AUTOSAR XML (schema 00046)
package /ComponentTypes
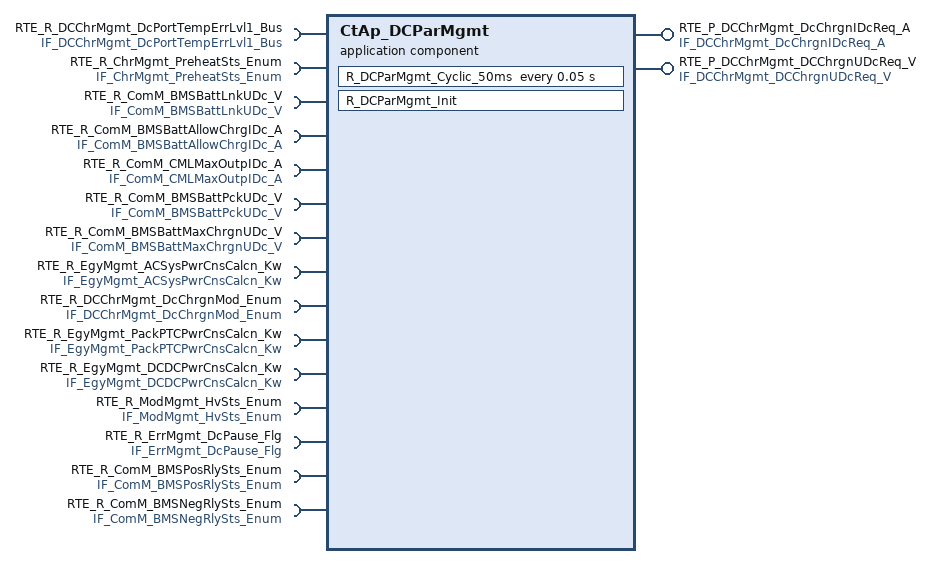
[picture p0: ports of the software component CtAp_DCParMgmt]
  application sw component type CtAp_DCParMgmt
    provide port RTE_P_DCChrMgmt_DcChrgnIDcReq_A: nonqueued-sender-com-spec{data-element=tec_DCChrMgmt_DcChrgnIDcReq_A, init-value=0}, provided-interface=IF_DCChrMgmt_DcChrgnIDcReq_A
    provide port RTE_P_DCChrMgmt_DCChrgnUDcReq_V: nonqueued-sender-com-spec{data-element=tec_DCChrMgmt_DcChrgnUDcReq_V, init-value=0}, provided-interface=IF_DCChrMgmt_DCChrgnUDcReq_V
    15 x require port:
      RTE_R_DCChrMgmt_DcPortTempErrLvl1_Bus: nonqueued-receiver-com-spec{data-element=tec_DCChrMgmt_DcPortTempErrLvl1_Bus, filter=data-filter-type=ALWAYS, init-value=fields=[DCChrMgmt_MonStatDcPortTempErrLvl1:0, DCChrMgmt_MonResDcPortTempErrLvl1:0, DCChrMgmt_ErrStatDcPortTempErrLvl1:0, DCChrMgmt_ErrResDcPortTempErrLvl1:0]}, required-interface=IF_DCChrMgmt_DcPortTempErrLvl1_Bus
      RTE_R_ChrMgmt_PreheatSts_Enum: nonqueued-receiver-com-spec{data-element=tec_ChrMgmt_PreheatSts_Enum, filter=data-filter-type=ALWAYS, init-value=0}, required-interface=IF_ChrMgmt_PreheatSts_Enum
      RTE_R_ComM_BMSBattLnkUDc_V: nonqueued-receiver-com-spec{data-element=tec_ComM_BMSBattLnkUDc_V, filter=data-filter-type=ALWAYS, init-value=0}, required-interface=IF_ComM_BMSBattLnkUDc_V
      RTE_R_ComM_BMSBattAllowChrgIDc_A: nonqueued-receiver-com-spec{data-element=tec_ComM_BMSBattAllowChrgIDc_A, filter=data-filter-type=ALWAYS, init-value=0}, required-interface=IF_ComM_BMSBattAllowChrgIDc_A
      RTE_R_ComM_CMLMaxOutpIDc_A: nonqueued-receiver-com-spec{data-element=tec_ComM_CMLMaxOutpIDc_A, filter=data-filter-type=ALWAYS, init-value=0}, required-interface=IF_ComM_CMLMaxOutpIDc_A
      RTE_R_ComM_BMSBattPckUDc_V: nonqueued-receiver-com-spec{data-element=tec_ComM_BMSBattPckUDc_V, filter=data-filter-type=ALWAYS, init-value=0}, required-interface=IF_ComM_BMSBattPckUDc_V
      RTE_R_ComM_BMSBattMaxChrgnUDc_V: nonqueued-receiver-com-spec{data-element=tec_ComM_BMSBattMaxChrgnUDc_V, filter=data-filter-type=ALWAYS, init-value=0}, required-interface=IF_ComM_BMSBattMaxChrgnUDc_V
      RTE_R_EgyMgmt_ACSysPwrCnsCalcn_Kw: nonqueued-receiver-com-spec{data-element=tec_EgyMgmt_ACSysPwrCnsCalcn_Kw, filter=data-filter-type=ALWAYS, init-value=0}, required-interface=IF_EgyMgmt_ACSysPwrCnsCalcn_Kw
      RTE_R_DCChrMgmt_DcChrgnMod_Enum: nonqueued-receiver-com-spec{data-element=tec_DCChrMgmt_DcChrgnMod_Enum, filter=data-filter-type=ALWAYS, init-value=0}, required-interface=IF_DCChrMgmt_DcChrgnMod_Enum
      RTE_R_EgyMgmt_PackPTCPwrCnsCalcn_Kw: nonqueued-receiver-com-spec{data-element=tec_EgyMgmt_PackPTCPwrCnsCalcn_Kw, filter=data-filter-type=ALWAYS, init-value=0}, required-interface=IF_EgyMgmt_PackPTCPwrCnsCalcn_Kw
      RTE_R_EgyMgmt_DCDCPwrCnsCalcn_Kw: nonqueued-receiver-com-spec{data-element=tec_EgyMgmt_DCDCPwrCnsCalcn_Kw, filter=data-filter-type=ALWAYS, init-value=0}, required-interface=IF_EgyMgmt_DCDCPwrCnsCalcn_Kw
      RTE_R_ModMgmt_HvSts_Enum: nonqueued-receiver-com-spec{data-element=tec_ModMgmt_HvSts_Enum, filter=data-filter-type=ALWAYS, init-value=0}, required-interface=IF_ModMgmt_HvSts_Enum
      RTE_R_ErrMgmt_DcPause_Flg: nonqueued-receiver-com-spec{data-element=tec_ErrMgmt_DcPause_Flg, filter=data-filter-type=ALWAYS, init-value=0}, required-interface=IF_ErrMgmt_DcPause_Flg
      RTE_R_ComM_BMSPosRlySts_Enum: nonqueued-receiver-com-spec{data-element=tec_ComM_BMSPosRlySts_Enum, filter=data-filter-type=ALWAYS, init-value=0}, required-interface=IF_ComM_BMSPosRlySts_Enum
      RTE_R_ComM_BMSNegRlySts_Enum: nonqueued-receiver-com-spec{data-element=tec_ComM_BMSNegRlySts_Enum, filter=data-filter-type=ALWAYS, init-value=0}, required-interface=IF_ComM_BMSNegRlySts_Enum
    behavior CtAp_DCParMgmt_InternalBehavior
      timing event TMT_R_DCParMgmt_Cyclic_50ms: start-on-event=R_DCParMgmt_Cyclic_50ms, period=0.05
      init event CtAp_DCParMgmt_InitEvent: start-on-event=R_DCParMgmt_Init
      runnable R_DCParMgmt_Cyclic_50ms
        data-receive-point-by-arguments:
          15 x access:
            REC_RTE_R_ChrMgmt_PreheatSts_Enum_tec_ChrMgmt_PreheatSts_Enum: accessed-variable=RTE_R_ChrMgmt_PreheatSts_Enum.tec_ChrMgmt_PreheatSts_Enum
            REC_RTE_R_ComM_BMSBattAllowChrgIDc_A_tec_ComM_BMSBattAllowChrgIDc_A: accessed-variable=RTE_R_ComM_BMSBattAllowChrgIDc_A.tec_ComM_BMSBattAllowChrgIDc_A
            REC_RTE_R_ComM_BMSBattLnkUDc_V_tec_ComM_BMSBattLnkUDc_V: accessed-variable=RTE_R_ComM_BMSBattLnkUDc_V.tec_ComM_BMSBattLnkUDc_V
            REC_RTE_R_ComM_BMSBattMaxChrgnUDc_V_tec_ComM_BMSBattMaxChrgnUDc_V: accessed-variable=RTE_R_ComM_BMSBattMaxChrgnUDc_V.tec_ComM_BMSBattMaxChrgnUDc_V
            REC_RTE_R_ComM_BMSBattPckUDc_V_tec_ComM_BMSBattPckUDc_V: accessed-variable=RTE_R_ComM_BMSBattPckUDc_V.tec_ComM_BMSBattPckUDc_V
            REC_RTE_R_ComM_CMLMaxOutpIDc_A_tec_ComM_CMLMaxOutpIDc_A: accessed-variable=RTE_R_ComM_CMLMaxOutpIDc_A.tec_ComM_CMLMaxOutpIDc_A
            REC_RTE_R_DCChrMgmt_DcChrgnMod_Enum_tec_DCChrMgmt_DcChrgnMod_Enum: accessed-variable=RTE_R_DCChrMgmt_DcChrgnMod_Enum.tec_DCChrMgmt_DcChrgnMod_Enum
            REC_RTE_R_DCChrMgmt_DcPortTempErrLvl1_Bus_tec_DCChrMgmt_DcPortTempErrLvl1_Bus: accessed-variable=RTE_R_DCChrMgmt_DcPortTempErrLvl1_Bus.tec_DCChrMgmt_DcPortTempErrLvl1_Bus
            REC_RTE_R_EgyMgmt_ACSysPwrCnsCalcn_Kw_tec_EgyMgmt_ACSysPwrCnsCalcn_Kw: accessed-variable=RTE_R_EgyMgmt_ACSysPwrCnsCalcn_Kw.tec_EgyMgmt_ACSysPwrCnsCalcn_Kw
            REC_RTE_R_EgyMgmt_DCDCPwrCnsCalcn_Kw_tec_EgyMgmt_DCDCPwrCnsCalcn_Kw: accessed-variable=RTE_R_EgyMgmt_DCDCPwrCnsCalcn_Kw.tec_EgyMgmt_DCDCPwrCnsCalcn_Kw
            REC_RTE_R_EgyMgmt_PackPTCPwrCnsCalcn_Kw_tec_EgyMgmt_PackPTCPwrCnsCalcn_Kw: accessed-variable=RTE_R_EgyMgmt_PackPTCPwrCnsCalcn_Kw.tec_EgyMgmt_PackPTCPwrCnsCalcn_Kw
            REC_RTE_R_ErrMgmt_DcPause_Flg_tec_ErrMgmt_DcPause_Flg: accessed-variable=RTE_R_ErrMgmt_DcPause_Flg.tec_ErrMgmt_DcPause_Flg
            REC_RTE_R_ModMgmt_HvSts_Enum_tec_ModMgmt_HvSts_Enum: accessed-variable=RTE_R_ModMgmt_HvSts_Enum.tec_ModMgmt_HvSts_Enum
            REC_RTE_R_ComM_BMSNegRlySts_Enum_tec_ComM_BMSNegRlySts_Enum: accessed-variable=RTE_R_ComM_BMSNegRlySts_Enum.tec_ComM_BMSNegRlySts_Enum
            REC_RTE_R_ComM_BMSPosRlySts_Enum_tec_ComM_BMSPosRlySts_Enum: accessed-variable=RTE_R_ComM_BMSPosRlySts_Enum.tec_ComM_BMSPosRlySts_Enum
        data-send-points:
          access SEND_RTE_P_DCChrMgmt_DCChrgnUDcReq_V_tec_DCChrMgmt_DcChrgnUDcReq_V: accessed-variable=RTE_P_DCChrMgmt_DCChrgnUDcReq_V.tec_DCChrMgmt_DcChrgnUDcReq_V
          access SEND_RTE_P_DCChrMgmt_DcChrgnIDcReq_A_tec_DCChrMgmt_DcChrgnIDcReq_A: accessed-variable=RTE_P_DCChrMgmt_DcChrgnIDcReq_A.tec_DCChrMgmt_DcChrgnIDcReq_A
      runnable R_DCParMgmt_Init
  swc implementation CtAp_DCParMgmt_Implementation: behavior=CtAp_DCParMgmt_InternalBehavior
